# MIMXRT1061 register map
Vendor: nxp.com; File version: 1.0
CPU: CM7 r0p1, little endian, MPU, FPU, VTOR, 4 interrupt priority bits
Registers are 32-bit, read-write, reset 0x0 unless marked. A register's access mark holds for its fields unless they carry their own. Offsets are from the block's base; [hi:lo] are bit positions; {n}, {i} and the like mark numbered series; 'fields as' and 'values as' point back to an identical list.

## CCM
Base 0x400FC000; register names take the prefix CCM_
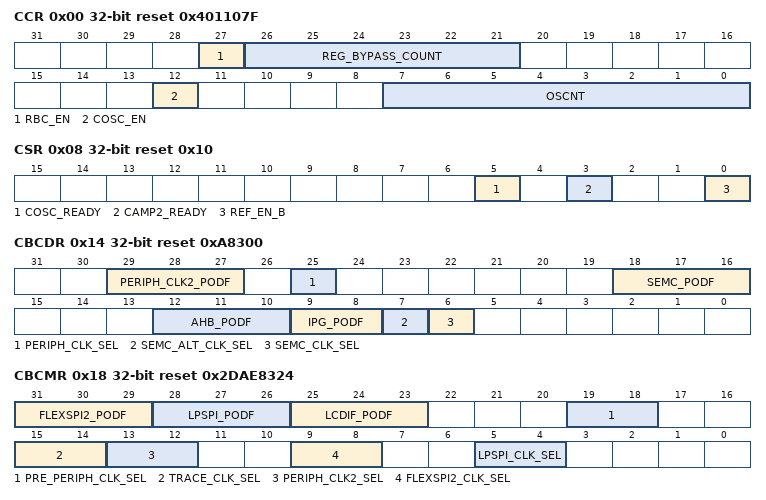
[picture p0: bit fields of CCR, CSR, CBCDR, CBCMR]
0x00 CCR reset 0x401107F — CCM Control Register
  [27] RBC_EN — Enable for REG_BYPASS_COUNTER
    0=REG_BYPASS_COUNTER disabled; 1=REG_BYPASS_COUNTER enabled
  [26:21] REG_BYPASS_COUNT — Counter for analog_reg_bypass signal assertion after standby voltage request by PMIC_STBY_REQ
    0=no delay; 1=1 CKIL clock period delay; 63=63 CKIL clock periods delay
  [12] COSC_EN — On chip oscillator enable bit - this bit value is reflected on the output cosc_en
    0=disable on chip oscillator; 1=enable on chip oscillator
  [7:0] OSCNT — Oscillator ready counter value. These bits define value of 32KHz counter, that serve as counter for oscillator lock time (count to n+1 ckil's). This is used for oscillator lock time. Current estimation is ~5ms. This counter will be used in ignition sequence and in wake from stop sequence if sbyos bit was defined, to notify that on chip oscillator output is ready for the dpll_ip to use and only then the gate in dpll_ip can be opened.
0x08 CSR ro reset 0x10 — CCM Status Register
  [5] COSC_READY — Status indication of on board oscillator
    0=on board oscillator is not ready; 1=on board oscillator is ready
  [3] CAMP2_READY — Status indication of CAMP2.
    0=CAMP2 is not ready; 1=CAMP2 is ready
  [0] REF_EN_B — Status of the value of CCM_REF_EN_B output of ccm
    0=value of CCM_REF_EN_B is '0'; 1=value of CCM_REF_EN_B is '1'
0x0C CCSR reset 0x100 — CCM Clock Switcher Register
  [0] PLL3_SW_CLK_SEL — Selects source to generate pll3_sw_clk. This bit should only be used for testing purposes.
    0=pll3_main_clk; 1=pll3 bypass clock
0x10 CACRR reset 0x1 — CCM Arm Clock Root Register
  [2:0] ARM_PODF — Divider for Arm clock root
    {v}=divide by {v+1} (v=0..7)
0x14 CBCDR reset 0xA8300 — CCM Bus Clock Divider Register
  [29:27] PERIPH_CLK2_PODF — Divider for periph_clk2_podf.
    {v}=divide by {v+1} (v=0..7)
  [25] PERIPH_CLK_SEL — Selector for peripheral main clock
    0=derive clock from pre_periph_clk_sel; 1=derive clock from periph_clk2_clk_divided
  [18:16] SEMC_PODF — Post divider for SEMC clock
    {v}=divide by {v+1} (v=0..7)
  [12:10] AHB_PODF — Divider for AHB PODF
    {v}=divide by {v+1} (v=0..7)
  [9:8] IPG_PODF — Divider for ipg podf.
    {v}=divide by {v+1} (v=0..3)
  [7] SEMC_ALT_CLK_SEL — SEMC alternative clock select
    0=PLL2 PFD2 will be selected as alternative clock for SEMC root clock; 1=PLL3 PFD1 will be selected as alternative clock for SEMC root clock
  [6] SEMC_CLK_SEL — SEMC clock source select
    0=Periph_clk output will be used as SEMC clock root; 1=SEMC alternative clock will be used as SEMC clock root
0x18 CBCMR reset 0x2DAE8324 — CCM Bus Clock Multiplexer Register
  [31:29] FLEXSPI2_PODF — Divider for flexspi2 clock root.
    {v}=divide by {v+1} (v=0..7)
  [28:26] LPSPI_PODF — Divider for LPSPI. Divider should be updated when output clock is gated.
    {v}=divide by {v+1} (v=0..7)
  [25:23] LCDIF_PODF — Post-divider for LCDIF clock.
    {v}=divide by {v+1} (v=0..7)
  [19:18] PRE_PERIPH_CLK_SEL — Selector for pre_periph clock multiplexer
    0=derive clock from PLL2; 1=derive clock from PLL2 PFD2; 2=derive clock from PLL2 PFD0; 3=derive clock from divided PLL1
  [15:14] TRACE_CLK_SEL — Selector for Trace clock multiplexer
    0=derive clock from PLL2; 1=derive clock from PLL2 PFD2; 2=derive clock from PLL2 PFD0; 3=derive clock from PLL2 PFD1
  [13:12] PERIPH_CLK2_SEL — Selector for peripheral clk2 clock multiplexer
    0=derive clock from pll3_sw_clk; 1=derive clock from osc_clk (pll1_ref_clk); 2=derive clock from pll2_bypass_clk
  [9:8] FLEXSPI2_CLK_SEL — Selector for flexspi2 clock multiplexer
    0=derive clock from PLL2 PFD2; 1=derive clock from PLL3 PFD0; 2=derive clock from PLL3 PFD1; 3=derive clock from PLL2 (pll2_main_clk)
  [5:4] LPSPI_CLK_SEL — Selector for lpspi clock multiplexer
    0=derive clock from PLL3 PFD1 clk; 1=derive clock from PLL3 PFD0; 2=derive clock from PLL2; 3=derive clock from PLL2 PFD2
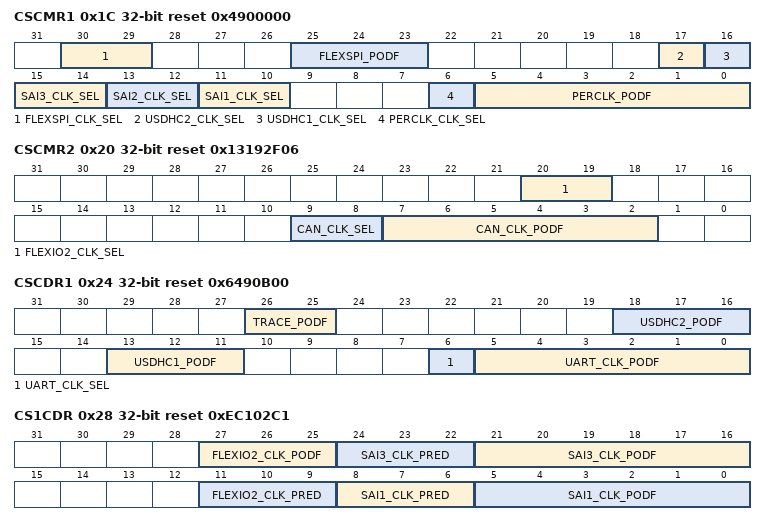
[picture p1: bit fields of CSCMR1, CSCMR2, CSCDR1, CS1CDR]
0x1C CSCMR1 reset 0x4900000 — CCM Serial Clock Multiplexer Register 1
  [30:29] FLEXSPI_CLK_SEL — Selector for flexspi clock multiplexer
    0=derive clock from semc_clk_root_pre; 1=derive clock from pll3_sw_clk; 2=derive clock from PLL2 PFD2; 3=derive clock from PLL3 PFD0
  [25:23] FLEXSPI_PODF — Divider for flexspi clock root.
    {v}=divide by {v+1} (v=0..7)
  [17] USDHC2_CLK_SEL — Selector for usdhc2 clock multiplexer
    0=derive clock from PLL2 PFD2; 1=derive clock from PLL2 PFD0
  [16] USDHC1_CLK_SEL — Selector for usdhc1 clock multiplexer
    0=derive clock from PLL2 PFD2; 1=derive clock from PLL2 PFD0
  [15:14] SAI3_CLK_SEL — Selector for sai3/adc1/adc2 clock multiplexer
    0=derive clock from PLL3 PFD2; 1=derive clock from PLL5; 2=derive clock from PLL4
  [13:12] SAI2_CLK_SEL — Selector for sai2 clock multiplexer
    values as SAI3_CLK_SEL
  [11:10] SAI1_CLK_SEL — Selector for sai1 clock multiplexer
    values as SAI3_CLK_SEL
  [6] PERCLK_CLK_SEL — Selector for the perclk clock multiplexor
    0=derive clock from ipg clk root; 1=derive clock from osc_clk
  [5:0] PERCLK_PODF — Divider for perclk podf.
    {v}=DIVIDE_{v+1} (Divide by {v+1}) (v=0..63)
0x20 CSCMR2 reset 0x13192F06 — CCM Serial Clock Multiplexer Register 2
  [20:19] FLEXIO2_CLK_SEL — Selector for flexio2/flexio3 clock multiplexer
    0=derive clock from PLL4 divided clock; 1=derive clock from PLL3 PFD2 clock; 2=derive clock from PLL5 clock; 3=derive clock from pll3_sw_clk
  [9:8] CAN_CLK_SEL — Selector for CAN/CANFD clock multiplexer
    0=derive clock from pll3_sw_clk divided clock (60M); 1=derive clock from osc_clk (24M); 2=derive clock from pll3_sw_clk divided clock (80M); 3=Disable FlexCAN clock
  [7:2] CAN_CLK_PODF — Divider for CAN/CANFD clock podf.
    {v}=DIVIDE_{v+1} (Divide by {v+1}) (v=0..63)
0x24 CSCDR1 reset 0x6490B00 — CCM Serial Clock Divider Register 1
  [26:25] TRACE_PODF — Divider for trace clock. Divider should be updated when output clock is gated.
    {v}=divide by {v+1} (v=0..3)
  [18:16] USDHC2_PODF — Divider for usdhc2 clock. Divider should be updated when output clock is gated.
    {v}=divide by {v+1} (v=0..7)
  [13:11] USDHC1_PODF — Divider for usdhc1 clock podf. Divider should be updated when output clock is gated.
    {v}=divide by {v+1} (v=0..7)
  [6] UART_CLK_SEL — Selector for the UART clock multiplexor
    0=derive clock from pll3_80m; 1=derive clock from osc_clk
  [5:0] UART_CLK_PODF — Divider for uart clock podf.
    {v}=DIVIDE_{v+1} (Divide by {v+1}) (v=0..63)
0x28 CS1CDR reset 0xEC102C1 — CCM Clock Divider Register
  [27:25] FLEXIO2_CLK_PODF — Divider for flexio2/flexio3 clock. Divider should be updated when output clock is gated.
    {v}=DIVIDE_{v+1} (Divide by {v+1}) (v=0..7)
  [24:22] SAI3_CLK_PRED — Divider for sai3/adc1/adc2 clock pred.
    {v}=divide by {v+1} (v=0..7)
  [21:16] SAI3_CLK_PODF — Divider for sai3 clock podf. The input clock to this divider should be lower than 300Mhz, the predivider can be used to achieve this.
    {v}=DIVIDE_{v+1} (Divide by {v+1}) (v=0..63)
  [11:9] FLEXIO2_CLK_PRED — Divider for flexio2/flexio3 clock.
    {v}=divide by {v+1} (v=0..7)
  [8:6] SAI1_CLK_PRED — Divider for sai1 clock pred.
    {v}=divide by {v+1} (v=0..7)
  [5:0] SAI1_CLK_PODF — Divider for sai1 clock podf. The input clock to this divider should be lower than 300Mhz, the predivider can be used to achieve this.
    {v}=DIVIDE_{v+1} (Divide by {v+1}) (v=0..63)
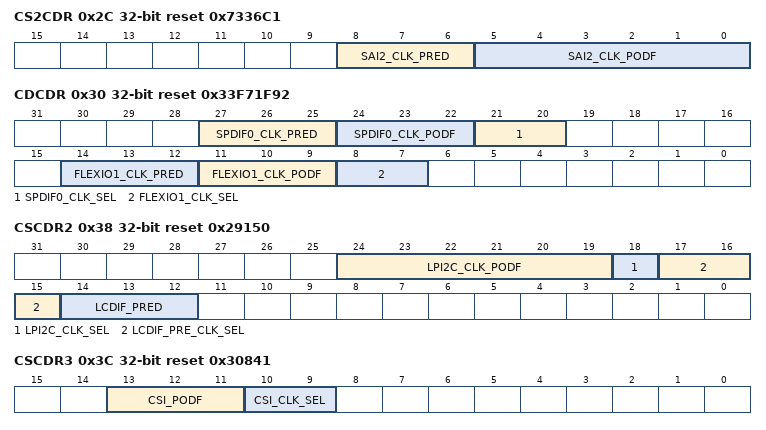
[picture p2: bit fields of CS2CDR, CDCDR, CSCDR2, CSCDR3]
0x2C CS2CDR reset 0x7336C1 — CCM Clock Divider Register
  [8:6] SAI2_CLK_PRED — Divider for sai2 clock pred.Divider should be updated when output clock is gated.
    {v}=divide by {v+1} (v=0..7)
  [5:0] SAI2_CLK_PODF — Divider for sai2 clock podf. The input clock to this divider should be lower than 300Mhz, the predivider can be used to achieve this.
    {v}=DIVIDE_{v+1} (Divide by {v+1}) (v=0..63)
0x30 CDCDR reset 0x33F71F92 — CCM D1 Clock Divider Register
  [27:25] SPDIF0_CLK_PRED — Divider for spdif0 clock pred. Divider should be updated when output clock is gated.
    {v}=DIVIDE_{v+1} (Divide by {v+1}) (v=0..7)
  [24:22] SPDIF0_CLK_PODF — Divider for spdif0 clock podf. Divider should be updated when output clock is gated.
    {v}=DIVIDE_{v+1} (Divide by {v+1}) (v=0..7)
  [21:20] SPDIF0_CLK_SEL — Selector for spdif0 clock multiplexer
    0=derive clock from PLL4; 1=derive clock from PLL3 PFD2; 2=derive clock from PLL5; 3=derive clock from pll3_sw_clk
  [14:12] FLEXIO1_CLK_PRED — Divider for flexio1 clock pred. Divider should be updated when output clock is gated.
    {v}=DIVIDE_{v+1} (Divide by {v+1}) (v=0..7)
  [11:9] FLEXIO1_CLK_PODF — Divider for flexio1 clock podf. Divider should be updated when output clock is gated.
    {v}=DIVIDE_{v+1} (Divide by {v+1}) (v=0..7)
  [8:7] FLEXIO1_CLK_SEL — Selector for flexio1 clock multiplexer
    values as SPDIF0_CLK_SEL
0x38 CSCDR2 reset 0x29150 — CCM Serial Clock Divider Register 2
  [24:19] LPI2C_CLK_PODF — Divider for lpi2c clock podf. Divider should be updated when output clock is gated. The input clock to this divider should be lower than 300Mhz, the predivider can be used to achieve this.
    {v}=DIVIDE_{v+1} (Divide by {v+1}) (v=0..63)
  [18] LPI2C_CLK_SEL — Selector for the LPI2C clock multiplexor
    0=derive clock from pll3_60m; 1=derive clock from osc_clk
  [17:15] LCDIF_PRE_CLK_SEL — Selector for lcdif root clock pre-multiplexer
    0=derive clock from PLL2; 1=derive clock from PLL3 PFD3; 2=derive clock from PLL5; 3=derive clock from PLL2 PFD0; 4=derive clock from PLL2 PFD1; 5=derive clock from PLL3 PFD1
  [14:12] LCDIF_PRED — Pre-divider for lcdif clock. Divider should be updated when output clock is gated.
    {v}=divide by {v+1} (v=0..7)
0x3C CSCDR3 reset 0x30841 — CCM Serial Clock Divider Register 3
  [13:11] CSI_PODF — Post divider for csi_mclk. Divider should be updated when output clock is gated.
    {v}=divide by {v+1} (v=0..7)
  [10:9] CSI_CLK_SEL — Selector for csi_mclk multiplexer
    0=derive clock from osc_clk (24M); 1=derive clock from PLL2 PFD2; 2=derive clock from pll3_120M; 3=derive clock from PLL3 PFD1
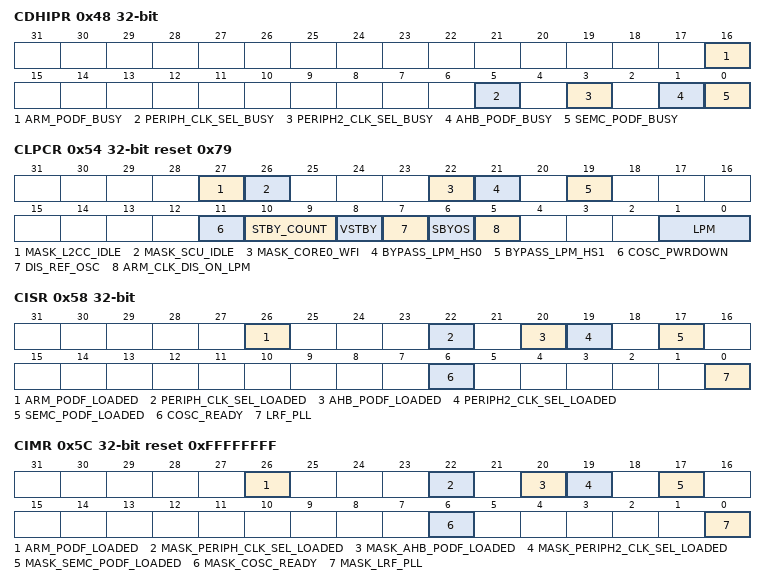
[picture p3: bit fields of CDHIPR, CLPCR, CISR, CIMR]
0x48 CDHIPR ro — CCM Divider Handshake In-Process Register
  [16] ARM_PODF_BUSY — Busy indicator for arm_podf.
    0=divider is not busy and its value represents the actual division; 1=divider is busy with handshake process with module. The value read in the divider represents the previous value of the division factor, and after the handshake the written value of the arm_podf will be applied.
  [5] PERIPH_CLK_SEL_BUSY — Busy indicator for periph_clk_sel mux control.
    0=mux is not busy and its value represents the actual division; 1=mux is busy with handshake process with module. The value read in the periph_clk_sel represents the previous value of select, and after the handshake periph_clk_sel value will be applied.
  [3] PERIPH2_CLK_SEL_BUSY — Busy indicator for periph2_clk_sel mux control.
    0=mux is not busy and its value represents the actual division; 1=mux is busy with handshake process with module. The value read in the periph2_clk_sel represents the previous value of select, and after the handshake periph2_clk_sel value will be applied.
  [1] AHB_PODF_BUSY — Busy indicator for ahb_podf.
    0=divider is not busy and its value represents the actual division; 1=divider is busy with handshake process with module. The value read in the divider represents the previous value of the division factor, and after the handshake the written value of the ahb_podf will be applied.
  [0] SEMC_PODF_BUSY — Busy indicator for semc_podf.
    0=divider is not busy and its value represents the actual division; 1=divider is busy with handshake process with module. The value read in the divider represents the previous value of the division factor, and after the handshake the written value of the semc_podf will be applied.
0x54 CLPCR reset 0x79 — CCM Low Power Control Register
  [27] MASK_L2CC_IDLE — Mask L2CC IDLE for entering low power mode
    0=L2CC IDLE is not masked; 1=L2CC IDLE is masked
  [26] MASK_SCU_IDLE — Mask SCU IDLE for entering low power mode Assertion of all bits[27:22] will generate low power mode request
    0=SCU IDLE is not masked; 1=SCU IDLE is masked
  [22] MASK_CORE0_WFI — Mask WFI of core0 for entering low power mode Assertion of all bits[27:22] will generate low power mode request
    0=WFI of core0 is not masked; 1=WFI of core0 is masked
  [21] BYPASS_LPM_HS0 — Bypass low power mode handshake. This bit should always be set to 1'b1 by software.
  [19] BYPASS_LPM_HS1 — Bypass low power mode handshake. This bit should always be set to 1'b1 by software.
  [11] COSC_PWRDOWN — In run mode, software can manually control powering down of on chip oscillator, i
    0=On chip oscillator will not be powered down, i.e. cosc_pwrdown = '0'.; 1=On chip oscillator will be powered down, i.e. cosc_pwrdown = '1'.
  [10:9] STBY_COUNT — Standby counter definition
    0=CCM will wait (1*pmic_delay_scaler)+1 ckil clock cycles; 1=CCM will wait (3*pmic_delay_scaler)+1 ckil clock cycles; 2=CCM will wait (7*pmic_delay_scaler)+1 ckil clock cycles; 3=CCM will wait (15*pmic_delay_scaler)+1 ckil clock cycles
  [8] VSTBY — Voltage standby request bit
    0=Voltage will not be changed to standby voltage after next entrance to STOP mode. ( PMIC_STBY_REQ will remain negated - '0'); 1=Voltage will be requested to change to standby voltage after next entrance to stop mode. ( PMIC_STBY_REQ will be asserted - '1').
  [7] DIS_REF_OSC — dis_ref_osc - in run mode, software can manually control closing of external reference oscillator clock, i
    0=external high frequency oscillator will be enabled, i.e. CCM_REF_EN_B = '0'.; 1=external high frequency oscillator will be disabled, i.e. CCM_REF_EN_B = '1'
  [6] SBYOS — Standby clock oscillator bit
    0=On-chip oscillator will not be powered down, after next entrance to STOP mode. (CCM_REF_EN_B will remain asserted - '0' and cosc_pwrdown will remain de asserted - '0'); 1=On-chip oscillator will be powered down, after next entrance to STOP mode. (CCM_REF_EN_B will be deasserted - '1' and cosc_pwrdown will be asserted - '1'). When returning from STOP mode, external oscillator will be enabled again, on-chip oscillator will return to oscillator mode, and after oscnt count, CCM will continue with the exit from the STOP mode process.
  [5] ARM_CLK_DIS_ON_LPM — Define if Arm clocks (arm_clk, soc_mxclk, soc_pclk, soc_dbg_pclk, vl_wrck) will be disabled on wait mode
    0=Arm clock enabled on wait mode; 1=Arm clock disabled on wait mode. .
  [1:0] LPM — Setting the low power mode that system will enter on next assertion of dsm_request signal.
    0=Remain in run mode; 1=Transfer to wait mode; 2=Transfer to stop mode
0x58 CISR write-1-clears — CCM Interrupt Status Register
  [26] ARM_PODF_LOADED write-1-clears — CCM interrupt request 1 generated due to frequency change of arm_podf
    0=interrupt is not generated due to frequency change of arm_podf; 1=interrupt generated due to frequency change of arm_podf
  [22] PERIPH_CLK_SEL_LOADED write-1-clears — CCM interrupt request 1 generated due to update of periph_clk_sel.
    0=interrupt is not generated due to update of periph_clk_sel; 1=interrupt generated due to update of periph_clk_sel
  [20] AHB_PODF_LOADED write-1-clears — CCM interrupt request 1 generated due to frequency change of ahb_podf
    0=interrupt is not generated due to frequency change of ahb_podf; 1=interrupt generated due to frequency change of ahb_podf
  [19] PERIPH2_CLK_SEL_LOADED write-1-clears — CCM interrupt request 1 generated due to frequency change of periph2_clk_sel
    0=interrupt is not generated due to frequency change of periph2_clk_sel; 1=interrupt generated due to frequency change of periph2_clk_sel
  [17] SEMC_PODF_LOADED write-1-clears — CCM interrupt request 1 generated due to frequency change of semc_podf
    0=interrupt is not generated due to frequency change of semc_podf; 1=interrupt generated due to frequency change of semc_podf
  [6] COSC_READY write-1-clears — CCM interrupt request 2 generated due to on board oscillator ready, i
    0=interrupt is not generated due to on board oscillator ready; 1=interrupt generated due to on board oscillator ready
  [0] LRF_PLL write-1-clears — CCM interrupt request 2 generated due to lock of all enabled and not bypaseed PLLs
    0=interrupt is not generated due to lock ready of all enabled and not bypaseed PLLs; 1=interrupt generated due to lock ready of all enabled and not bypaseed PLLs
0x5C CIMR reset 0xFFFFFFFF — CCM Interrupt Mask Register
  [26] ARM_PODF_LOADED — mask interrupt generation due to frequency change of arm_podf
    0=don't mask interrupt due to frequency change of arm_podf - interrupt will be created; 1=mask interrupt due to frequency change of arm_podf
  [22] MASK_PERIPH_CLK_SEL_LOADED — mask interrupt generation due to update of periph_clk_sel.
    0=don't mask interrupt due to update of periph_clk_sel - interrupt will be created; 1=mask interrupt due to update of periph_clk_sel
  [20] MASK_AHB_PODF_LOADED — mask interrupt generation due to frequency change of ahb_podf
    0=don't mask interrupt due to frequency change of ahb_podf - interrupt will be created; 1=mask interrupt due to frequency change of ahb_podf
  [19] MASK_PERIPH2_CLK_SEL_LOADED — mask interrupt generation due to update of periph2_clk_sel.
    0=don't mask interrupt due to update of periph2_clk_sel - interrupt will be created; 1=mask interrupt due to update of periph2_clk_sel
  [17] MASK_SEMC_PODF_LOADED — mask interrupt generation due to frequency change of semc_podf
    0=don't mask interrupt due to frequency change of semc_podf - interrupt will be created; 1=mask interrupt due to frequency change of semc_podf
  [6] MASK_COSC_READY — mask interrupt generation due to on board oscillator ready
    0=don't mask interrupt due to on board oscillator ready - interrupt will be created; 1=mask interrupt due to on board oscillator ready
  [0] MASK_LRF_PLL — mask interrupt generation due to lrf of PLLs
    0=don't mask interrupt due to lrf of PLLs - interrupt will be created; 1=mask interrupt due to lrf of PLLs
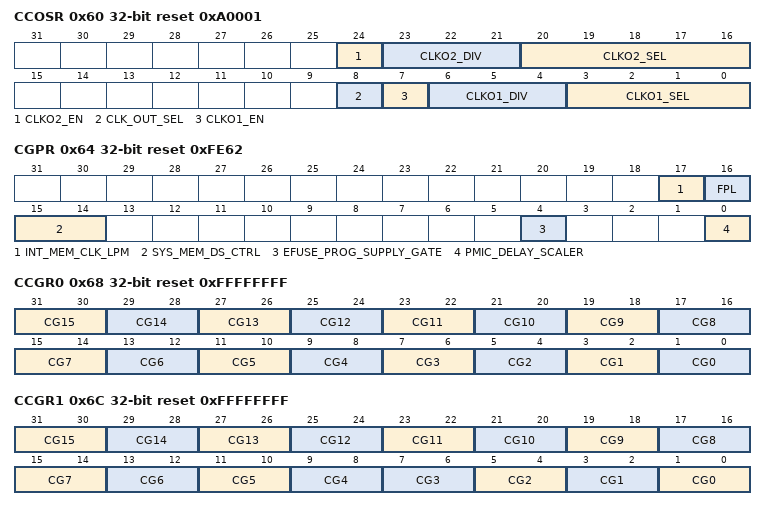
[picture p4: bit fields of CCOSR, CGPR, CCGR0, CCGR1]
0x60 CCOSR reset 0xA0001 — CCM Clock Output Source Register
  [24] CLKO2_EN — Enable of CCM_CLKO2 clock
    0=CCM_CLKO2 disabled; 1=CCM_CLKO2 enabled
  [23:21] CLKO2_DIV — Setting the divider of CCM_CLKO2
    {v}=divide by {v+1} (v=0..7)
  [20:16] CLKO2_SEL — Selection of the clock to be generated on CCM_CLKO2
    3=usdhc1_clk_root; 6=lpi2c_clk_root; 11=csi_clk_root; 14=osc_clk; 17=usdhc2_clk_root; 18=sai1_clk_root; 19=sai2_clk_root; 20=sai3_clk_root (shared with ADC1 and ADC2 alt_clk root); 23=can_clk_root (FlexCAN, shared with CANFD); 27=flexspi_clk_root; 28=uart_clk_root; 29=spdif0_clk_root
  [8] CLK_OUT_SEL — CCM_CLKO1 output to reflect CCM_CLKO1 or CCM_CLKO2 clocks
    0=CCM_CLKO1 output drives CCM_CLKO1 clock; 1=CCM_CLKO1 output drives CCM_CLKO2 clock
  [7] CLKO1_EN — Enable of CCM_CLKO1 clock
    0=CCM_CLKO1 disabled; 1=CCM_CLKO1 enabled
  [6:4] CLKO1_DIV — Setting the divider of CCM_CLKO1
    {v}=divide by {v+1} (v=0..7)
  [3:0] CLKO1_SEL — Selection of the clock to be generated on CCM_CLKO1
    0=USB1 PLL clock (divided by 2); 1=SYS PLL clock (divided by 2); 3=VIDEO PLL clock (divided by 2); 5=semc_clk_root; 10=lcdif_pix_clk_root; 11=ahb_clk_root; 12=ipg_clk_root; 13=perclk_root; 14=ckil_sync_clk_root; 15=pll4_main_clk
0x64 CGPR reset 0xFE62 — CCM General Purpose Register
  [17] INT_MEM_CLK_LPM — Control for the Deep Sleep signal to the Arm Platform memories with additional control logic based on the Arm WFI signal
    0=Disable the clock to the Arm platform memories when entering Low Power Mode; 1=Keep the clocks to the Arm platform memories enabled only if an interrupt is pending when entering Low Power Modes (WAIT and STOP without power gating)
  [16] FPL — Fast PLL enable.
    0=Engage PLL enable default way; 1=Engage PLL enable 3 CKIL clocks earlier at exiting low power mode (STOP). Should be used only if 24MHz OSC was active in low power mode.
  [15:14] SYS_MEM_DS_CTRL — System memory DS control
    0=Disable memory DS mode always; 1=Enable memory (outside Arm platform) DS mode when system STOP and PLL are disabled; 0b1x=enable memory (outside Arm platform) DS mode when system is in STOP mode
  [4] EFUSE_PROG_SUPPLY_GATE — Defines the value of the output signal cgpr_dout[4]. Gate of program supply for efuse programing
    0=fuse programing supply voltage is gated off to the efuse module; 1=allow fuse programing
  [0] PMIC_DELAY_SCALER — Defines clock dividion of clock for stby_count (pmic delay counter)
    0=clock is not divided; 1=clock is divided /8
0x68 CCGR0 reset 0xFFFFFFFF — CCM Clock Gating Register 0
  [31:30] CG15 — gpio2_clocks (gpio2_clk_enable)
  [29:28] CG14 — lpuart2 clock (lpuart2_clk_enable)
  [27:26] CG13 — gpt2 serial clocks (gpt2_serial_clk_enable)
  [25:24] CG12 — gpt2 bus clocks (gpt2_bus_clk_enable)
  [23:22] CG11 — trace clock (trace_clk_enable)
  [21:20] CG10 — can2_serial clock (can2_serial_clk_enable)
  [19:18] CG9 — can2 clock (can2_clk_enable)
  [17:16] CG8 — can1_serial clock (can1_serial_clk_enable)
  [15:14] CG7 — can1 clock (can1_clk_enable)
  [13:12] CG6 — lpuart3 clock (lpuart3_clk_enable)
  [11:10] CG5 — dcp clock (dcp_clk_enable)
  [9:8] CG4 — sim_m or sim_main register access clock (sim_m_mainclk_r_enable)
  [7:6] CG3 — Reserved
  [5:4] CG2 — mqs clock ( mqs_hmclk_clock_enable)
  [3:2] CG1 — aips_tz2 clocks (aips_tz2_clk_enable)
  [1:0] CG0 — aips_tz1 clocks (aips_tz1_clk_enable)
0x6C CCGR1 reset 0xFFFFFFFF — CCM Clock Gating Register 1
  [31:30] CG15 — gpio5 clock (gpio5_clk_enable)
  [29:28] CG14 — csu clock (csu_clk_enable)
  [27:26] CG13 — gpio1 clock (gpio1_clk_enable)
  [25:24] CG12 — lpuart4 clock (lpuart4_clk_enable)
  [23:22] CG11 — gpt1 serial clock (gpt_serial_clk_enable)
  [21:20] CG10 — gpt1 bus clock (gpt_clk_enable)
  [19:18] CG9 — semc_exsc clock (semc_exsc_clk_enable)
  [17:16] CG8 — adc1 clock (adc1_clk_enable)
  [15:14] CG7 — aoi2 clocks (aoi2_clk_enable)
  [13:12] CG6 — pit clocks (pit_clk_enable)
  [11:10] CG5 — enet clock (enet_clk_enable)
  [9:8] CG4 — adc2 clock (adc2_clk_enable)
  [2n+1:2n] CG{n} (n=0..3) — lpspi{n+1} clocks (lpspi{n+1}_clk_enable)
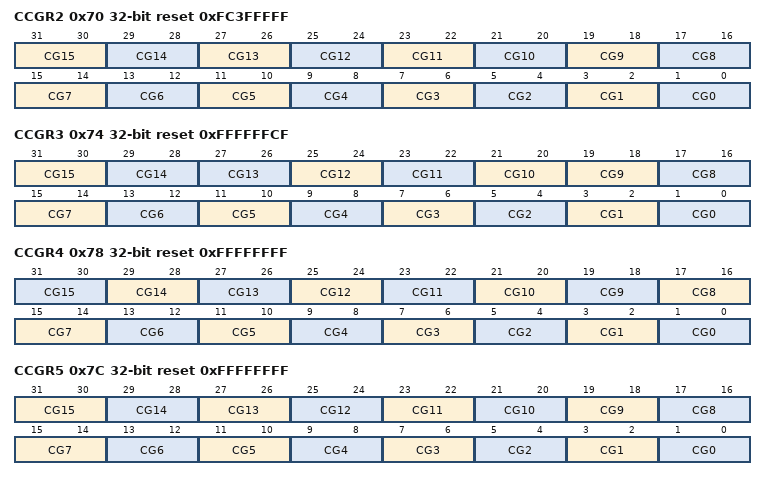
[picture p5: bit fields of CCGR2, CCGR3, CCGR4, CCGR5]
0x70 CCGR2 reset 0xFC3FFFFF — CCM Clock Gating Register 2
  [31:30] CG15 — pxp clocks (pxp_clk_enable)
  [29:28] CG14 — lcd clocks (lcd_clk_enable)
  [27:26] CG13 — gpio3 clock (gpio3_clk_enable)
  [25:24] CG12 — xbar2 clock (xbar2_clk_enable)
  [23:22] CG11 — xbar1 clock (xbar1_clk_enable)
  [21:20] CG10 — ipmux3 clock (ipmux3_clk_enable)
  [19:18] CG9 — ipmux2 clock (ipmux2_clk_enable)
  [17:16] CG8 — ipmux1 clock (ipmux1_clk_enable)
  [15:14] CG7 — xbar3 clock (xbar3_clk_enable)
  [13:12] CG6 — OCOTP_CTRL clock (ocotp_clk_enable)
  [11:10] CG5 — lpi2c3 clock (lpi2c3_clk_enable)
  [9:8] CG4 — lpi2c2 clock (lpi2c2_clk_enable)
  [7:6] CG3 — lpi2c1 clock (lpi2c1_clk_enable)
  [5:4] CG2 — iomuxc_snvs clock (iomuxc_snvs_clk_enable)
  [3:2] CG1 — csi clock (csi_clk_enable)
  [1:0] CG0 — ocram_exsc clock (ocram_exsc_clk_enable)
0x74 CCGR3 reset 0xFFFFFFCF — CCM Clock Gating Register 3
  [31:30] CG15 — iomuxc_snvs_gpr clock (iomuxc_snvs_gpr_clk_enable)
  [29:28] CG14 — The OCRAM clock cannot be turned off when the CM cache is running on this device.
  [2n+1:2n] CG{n} (n=10..13) — acmp{n-9} clocks (acmp{n-9}_clk_enable)
  [19:18] CG9 — flexram clock (flexram_clk_enable)
  [17:16] CG8 — wdog1 clock (wdog1_clk_enable)
  [15:14] CG7 — ewm clocks (ewm_clk_enable)
  [13:12] CG6 — gpio4 clock (gpio4_clk_enable)
  [11:10] CG5 — lcdif pix clock (lcdif_pix_clk_enable)
  [9:8] CG4 — aoi1 clock (aoi1_clk_enable)
  [7:6] CG3 — lpuart6 clock (lpuart6_clk_enable)
  [5:4] CG2 — semc clocks (semc_clk_enable)
  [3:2] CG1 — lpuart5 clock (lpuart5_clk_enable)
  [1:0] CG0 — flexio2 clocks (flexio2_clk_enable)
0x78 CCGR4 reset 0xFFFFFFFF — CCM Clock Gating Register 4
  [2n+1:2n] CG{n} (n=12..15) — qdc{n-11} clocks (qdc{n-11}_clk_enable)
  [2n+1:2n] CG{n} (n=8..11) — pwm{n-7} clocks (pwm{n-7}_clk_enable)
  [15:14] CG7 — sim_ems clocks (sim_ems_clk_enable)
  [13:12] CG6 — sim_m clocks (sim_m_clk_enable)
  [11:10] CG5 — tsc_dig clock (tsc_clk_enable)
  [9:8] CG4 — sim_m7 clock (sim_m7_clk_enable)
  [7:6] CG3 — bee clock(bee_clk_enable)
  [5:4] CG2 — iomuxc gpr clock (iomuxc_gpr_clk_enable)
  [3:2] CG1 — iomuxc clock (iomuxc_clk_enable)
  [1:0] CG0 — sim_m7 register access clock (sim_m7_mainclk_r_enable)
0x7C CCGR5 reset 0xFFFFFFFF — CCM Clock Gating Register 5
  [31:30] CG15 — snvs_lp clock (snvs_lp_clk_enable)
  [29:28] CG14 — snvs_hp clock (snvs_hp_clk_enable)
  [27:26] CG13 — lpuart7 clock (lpuart7_clk_enable)
  [25:24] CG12 — lpuart1 clock (lpuart1_clk_enable)
  [23:22] CG11 — sai3 clock (sai3_clk_enable)
  [21:20] CG10 — sai2 clock (sai2_clk_enable)
  [19:18] CG9 — sai1 clock (sai1_clk_enable)
  [17:16] CG8 — sim_main clock (sim_main_clk_enable)
  [15:14] CG7 — spdif clock (spdif_clk_enable)
  [13:12] CG6 — aipstz4 clocks (aips_tz4_clk_enable)
  [11:10] CG5 — wdog2 clock (wdog2_clk_enable)
  [9:8] CG4 — kpp clock (kpp_clk_enable)
  [7:6] CG3 — dma clock (dma_clk_enable)
  [5:4] CG2 — wdog3 clock (wdog3_clk_enable)
  [3:2] CG1 — flexio1 clock (flexio1_clk_enable)
  [1:0] CG0 — rom clock (rom_clk_enable)
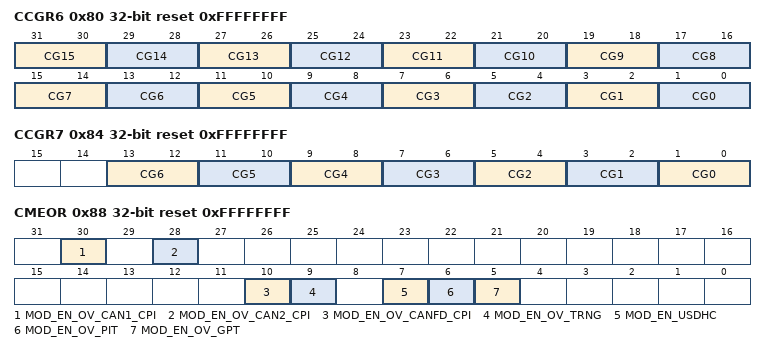
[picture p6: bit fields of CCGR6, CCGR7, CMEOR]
0x80 CCGR6 reset 0xFFFFFFFF — CCM Clock Gating Register 6
  [31:30] CG15 — timer3 clocks (timer3_clk_enable)
  [29:28] CG14 — timer2 clocks (timer2_clk_enable)
  [27:26] CG13 — timer1 clocks (timer1_clk_enable)
  [25:24] CG12 — lpi2c4 serial clock (lpi2c4_serial_clk_enable)
  [23:22] CG11 — anadig clocks (anadig_clk_enable)
  [21:20] CG10 — sim_per clock (sim_per_clk_enable) sim_axbs_p_clk_enable
  [19:18] CG9 — aips_tz3 clock (aips_tz3_clk_enable)
  [17:16] CG8 — timer4 clocks (timer4_clk_enable)
  [15:14] CG7 — lpuart8 clocks (lpuart8_clk_enable)
  [13:12] CG6 — trng clock (trng_clk_enable)
  [11:10] CG5 — flexspi clocks (flexspi_clk_enable) sim_ems_clk_enable must also be cleared, when flexspi_clk_enable is cleared
  [9:8] CG4 — ipmux4 clock (ipmux4_clk_enable)
  [7:6] CG3 — dcdc clocks (dcdc_clk_enable)
  [5:4] CG2 — usdhc2 clocks (usdhc2_clk_enable)
  [3:2] CG1 — usdhc1 clocks (usdhc1_clk_enable)
  [1:0] CG0 — usboh3 clock (usboh3_clk_enable)
0x84 CCGR7 reset 0xFFFFFFFF — CCM Clock Gating Register 7
  [13:12] CG6 — flexio3_clk_enable
  [11:10] CG5 — aips_lite_clk_enable
  [9:8] CG4 — can3_serial_clk_enable
  [7:6] CG3 — can3_clk_enable
  [5:4] CG2 — axbs_l_clk_enable
  [3:2] CG1 — flexspi2_clk_enable
  [1:0] CG0 — enet2_clk_enable
0x88 CMEOR reset 0xFFFFFFFF — CCM Module Enable Overide Register
  [30] MOD_EN_OV_CAN1_CPI — Overide clock enable signal from CAN1 - clock will not be gated based on CAN's signal 'enable_clk_cpi'
    0=don't overide module enable signal; 1=overide module enable signal
  [28] MOD_EN_OV_CAN2_CPI — Overide clock enable signal from CAN2 - clock will not be gated based on CAN's signal 'enable_clk_cpi'
    0=don't override module enable signal; 1=override module enable signal
  [10] MOD_EN_OV_CANFD_CPI — Overide clock enable signal from FlexCAN3(CANFD) - clock will not be gated based on CAN's signal 'enable_clk_cpi'
    values as MOD_EN_OV_CAN2_CPI
  [9] MOD_EN_OV_TRNG — Overide clock enable signal from TRNG
    values as MOD_EN_OV_CAN2_CPI
  [7] MOD_EN_USDHC — overide clock enable signal from USDHC.
    values as MOD_EN_OV_CAN2_CPI
  [6] MOD_EN_OV_PIT — Overide clock enable signal from PIT - clock will not be gated based on PIT's signal 'ipg_enable_clk'
    values as MOD_EN_OV_CAN2_CPI
  [5] MOD_EN_OV_GPT — Overide clock enable signal from GPT - clock will not be gated based on GPT's signal 'ipg_enable_clk'
    values as MOD_EN_OV_CAN2_CPI
